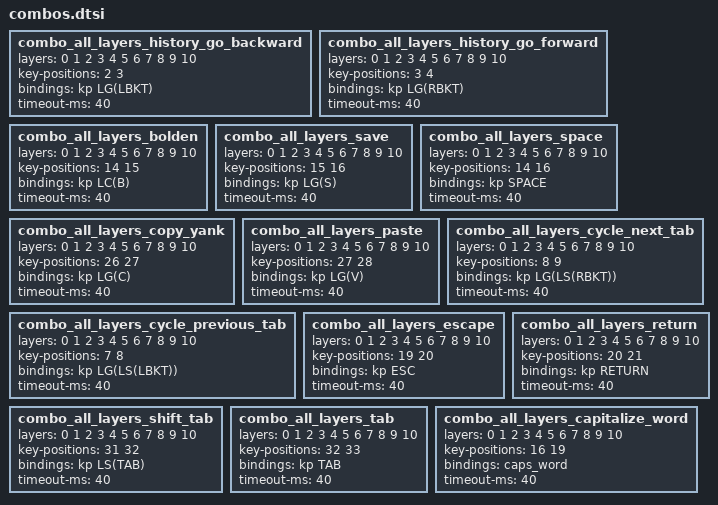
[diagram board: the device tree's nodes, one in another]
/* Combos */
/* Corne Layout is based on 6 columns and 3 thumb keys */
/* To keep this layout 5-column, we simply keep the 1st and 12th column empty */
/* */
/* Left Hand                             Right Hand */
/* ┌────┬────┬────┬────┬────┬────┐       ┌────┬────┬────┬────┬────┬────┐ */
/* │ (0)│  1 │  2 │  3 │  4 │  5 │       │  6 │  7 │  8 │  9 │ 10 │    │ */
/* ├────┼────┼────┼────┼────┼────┤       ├────┼────┼────┼────┼────┼────┤ */
/* │    │ 13 │ 14 │ 15 │ 16 │ 17 │       │ 18 │ 19 │ 20 │ 21 │ 22 │    │ */
/* ├────┼────┼────┼────┼────┼────┤       ├────┼────┼────┼────┼────┼────┤ */
/* │    │ 25 │ 26 │ 27 │ 28 │ 29 │       │ 30 │ 31 │ 32 │ 33 │ 34 │    │ */
/* ├────┼────┼────┼────┼────┼────┤       ├────┼────┼────┼────┼────┼────┤ */
/* │    │    │    │ 36 │ 37 │ 38 │       │ 39 │ 40 │ 41 │    │    │    │ */
/* └────┴────┴────┴────┴────┴────┘       └────┴────┴────┴────┴────┴────┘ */
/* */
/* ------------------------------ */
/* All Layers                     */
/* ------------------------------ */
/* */

/* ------------------------------ */
/*   History Go Backward          */
/* ------------------------------ */
/*   _ ▢ X X ▢ ▢    ▢ ▢ ▢ ▢ ▢ _   */
/*   _ ▢ ▢ ▢ ▢ ▢    ▢ ▢ ▢ ▢ ▢ _   */
/*   _ ▢ ▢ ▢ ▢ ▢    ▢ ▢ ▢ ▢ ▢ _   */
/*         ▢ ▢ ▢    ▢ ▢ ▢         */
/* ------------------------------ */

combo_all_layers_history_go_backward {
    layers = <0 1 2 3 4 5 6 7 8 9 10>;
    key-positions = <2 3>;
    bindings = <&kp LG(LBKT)>;
    timeout-ms = <40>;
};


/* ------------------------------ */
/*      History Go Forward        */
/* ------------------------------ */
/*   _ ▢ ▢ X X ▢    ▢ ▢ ▢ ▢ ▢ _   */
/*   _ ▢ ▢ ▢ ▢ ▢    ▢ ▢ ▢ ▢ ▢ _   */
/*   _ ▢ ▢ ▢ ▢ ▢    ▢ ▢ ▢ ▢ ▢ _   */
/*         ▢ ▢ ▢    ▢ ▢ ▢         */
/* ------------------------------ */

combo_all_layers_history_go_forward {
    layers = <0 1 2 3 4 5 6 7 8 9 10>;
    key-positions = <3 4>;
    bindings = <&kp LG(RBKT)>;
    timeout-ms = <40>;
};


/* ------------------------------ */
/*       Bolden                   */
/* ------------------------------ */
/*   _ ▢ ▢ ▢ ▢ ▢    ▢ ▢ ▢ ▢ ▢ _   */
/*   _ ▢ X X ▢ ▢    ▢ ▢ ▢ ▢ ▢ _   */
/*   _ ▢ ▢ ▢ ▢ ▢    ▢ ▢ ▢ ▢ ▢ _   */
/*         ▢ ▢ ▢    ▢ ▢ ▢         */
/* ------------------------------ */

combo_all_layers_bolden {
    layers = <0 1 2 3 4 5 6 7 8 9 10>;
    key-positions = <14 15>;
    bindings = <&kp LC(B)>;
    timeout-ms = <40>;
};


/* ------------------------------ */
/*     Save                       */
/* ------------------------------ */
/*   _ ▢ ▢ ▢ ▢ ▢    ▢ ▢ ▢ ▢ ▢ _   */
/*   _ ▢ ▢ X X ▢    ▢ ▢ ▢ ▢ ▢ _   */
/*   _ ▢ ▢ ▢ ▢ ▢    ▢ ▢ ▢ ▢ ▢ _   */
/*         ▢ ▢ ▢    ▢ ▢ ▢         */
/* ------------------------------ */

combo_all_layers_save {
    layers = <0 1 2 3 4 5 6 7 8 9 10>;
    key-positions = <15 16>;
    bindings = <&kp LG(S)>;
    timeout-ms = <40>;
};


/* ------------------------------ */
/*      Space                     */
/* ------------------------------ */
/*   _ ▢ ▢ ▢ ▢ ▢    ▢ ▢ ▢ ▢ ▢ _   */
/*   _ ▢ X ▢ X ▢    ▢ ▢ ▢ ▢ ▢ _   */
/*   _ ▢ ▢ ▢ ▢ ▢    ▢ ▢ ▢ ▢ ▢ _   */
/*         ▢ ▢ ▢    ▢ ▢ ▢         */
/* ------------------------------ */

combo_all_layers_space {
    layers = <0 1 2 3 4 5 6 7 8 9 10>;
    key-positions = <14 16>;
    bindings = <&kp SPACE>;
    timeout-ms = <40>;
};


/* ------------------------------ */
/*      Copy                      */
/* ------------------------------ */
/*   _ ▢ ▢ ▢ ▢ ▢    ▢ ▢ ▢ ▢ ▢ _   */
/*   _ ▢ ▢ ▢ ▢ ▢    ▢ ▢ ▢ ▢ ▢ _   */
/*   _ ▢ X X ▢ ▢    ▢ ▢ ▢ ▢ ▢ _   */
/*         ▢ ▢ ▢    ▢ ▢ ▢         */
/* ------------------------------ */

combo_all_layers_copy_yank {
    layers = <0 1 2 3 4 5 6 7 8 9 10>;
    key-positions = <26 27>;
    bindings = <&kp LG(C)>;
    timeout-ms = <40>;
};


/* ------------------------------ */
/*      Paste                     */
/* ------------------------------ */
/*   _ ▢ ▢ ▢ ▢ ▢    ▢ ▢ ▢ ▢ ▢ _   */
/*   _ ▢ ▢ ▢ ▢ ▢    ▢ ▢ ▢ ▢ ▢ _   */
/*   _ ▢ ▢ X X ▢    ▢ ▢ ▢ ▢ ▢ _   */
/*         ▢ ▢ ▢    ▢ ▢ ▢         */
/* ------------------------------ */

combo_all_layers_paste {
    layers = <0 1 2 3 4 5 6 7 8 9 10>;
    key-positions = <27 28>;
    bindings = <&kp LG(V)>;
    timeout-ms = <40>;
};


/* ------------------------------ */
/*      Cycle Previous Tab        */
/* ------------------------------ */
/*   _ ▢ ▢ ▢ ▢ ▢    ▢ X X ▢ ▢ _   */
/*   _ ▢ ▢ ▢ ▢ ▢    ▢ ▢ ▢ ▢ ▢ _   */
/*   _ ▢ ▢ ▢ ▢ ▢    ▢ ▢ ▢ ▢ ▢ _   */
/*         ▢ ▢ ▢    ▢ ▢ ▢         */
/* ------------------------------ */

combo_all_layers_cycle_previous_tab {
    layers = <0 1 2 3 4 5 6 7 8 9 10>;
    key-positions = <7 8>;
    bindings = <&kp LG(LS(LBKT))>;
    timeout-ms = <40>;
};


/* ------------------------------ */
/*      Cycle Next Tab            */
/* ------------------------------ */
/*   _ ▢ ▢ ▢ ▢ ▢    ▢ ▢ X X ▢ _   */
/*   _ ▢ ▢ ▢ ▢ ▢    ▢ ▢ ▢ ▢ ▢ _   */
/*   _ ▢ ▢ ▢ ▢ ▢    ▢ ▢ ▢ ▢ ▢ _   */
/*         ▢ ▢ ▢    ▢ ▢ ▢         */
/* ------------------------------ */

combo_all_layers_cycle_next_tab {
    layers = <0 1 2 3 4 5 6 7 8 9 10>;
    key-positions = <8 9>;
    bindings = <&kp LG(LS(RBKT))>;
    timeout-ms = <40>;
};


/* ------------------------------ */
/*      Escape                    */
/* ------------------------------ */
/*   _ ▢ ▢ ▢ ▢ ▢    ▢ ▢ ▢ ▢ ▢ _   */
/*   _ ▢ ▢ ▢ ▢ ▢    ▢ X X ▢ ▢ _   */
/*   _ ▢ ▢ ▢ ▢ ▢    ▢ ▢ ▢ ▢ ▢ _   */
/*         ▢ ▢ ▢    ▢ ▢ ▢         */
/* ------------------------------ */

combo_all_layers_escape {
    layers = <0 1 2 3 4 5 6 7 8 9 10>;
    key-positions = <19 20>;
    bindings = <&kp ESC>;
    timeout-ms = <40>;
};


/* ------------------------------ */
/*      Return                    */
/* ------------------------------ */
/*   _ ▢ ▢ ▢ ▢ ▢    ▢ ▢ ▢ ▢ ▢ _   */
/*   _ ▢ ▢ ▢ ▢ ▢    ▢ ▢ X X ▢ _   */
/*   _ ▢ ▢ ▢ ▢ ▢    ▢ ▢ ▢ ▢ ▢ _   */
/*         ▢ ▢ ▢    ▢ ▢ ▢         */
/* ------------------------------ */

combo_all_layers_return {
    layers = <0 1 2 3 4 5 6 7 8 9 10>;
    key-positions = <20 21>;
    bindings = <&kp RETURN>;
    timeout-ms = <40>;
};


/* ------------------------------ */
/*      Shift Tab                 */
/* ------------------------------ */
/*   _ ▢ ▢ ▢ ▢ ▢    ▢ ▢ ▢ ▢ ▢ _   */
/*   _ ▢ ▢ ▢ ▢ ▢    ▢ ▢ ▢ ▢ ▢ _   */
/*   _ ▢ ▢ ▢ ▢ ▢    ▢ X X ▢ ▢ _   */
/*         ▢ ▢ ▢    ▢ ▢ ▢         */
/* ------------------------------ */

combo_all_layers_shift_tab {
    layers = <0 1 2 3 4 5 6 7 8 9 10>;
    key-positions = <31 32>;
    bindings = <&kp LS(TAB)>;
    timeout-ms = <40>;
};


/* ------------------------------ */
/*      Tab                       */
/* ------------------------------ */
/*   _ ▢ ▢ ▢ ▢ ▢    ▢ ▢ ▢ ▢ ▢ _   */
/*   _ ▢ ▢ ▢ ▢ ▢    ▢ ▢ ▢ ▢ ▢ _   */
/*   _ ▢ ▢ ▢ ▢ ▢    ▢ ▢ X X ▢ _   */
/*         ▢ ▢ ▢    ▢ ▢ ▢         */
/* ------------------------------ */

combo_all_layers_tab {
    layers = <0 1 2 3 4 5 6 7 8 9 10>;
    key-positions = <32 33>;
    bindings = <&kp TAB>;
    timeout-ms = <40>;
};


/* ------------------------------ */
/*      Capitalize Word           */
/* ------------------------------ */
/*   _ ▢ ▢ ▢ ▢ ▢    ▢ ▢ ▢ ▢ ▢ _   */
/*   _ ▢ ▢ ▢ X ▢    ▢ X ▢ ▢ ▢ _   */
/*   _ ▢ ▢ ▢ ▢ ▢    ▢ ▢ ▢ ▢ ▢ _   */
/*         ▢ ▢ ▢    ▢ ▢ ▢         */
/* ------------------------------ */

combo_all_layers_capitalize_word {
    layers = <0 1 2 3 4 5 6 7 8 9 10>;
    key-positions = <16 19>;
    bindings = <&caps_word>;
    timeout-ms = <40>;
};


